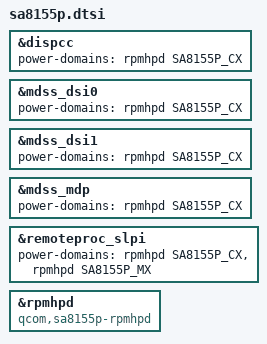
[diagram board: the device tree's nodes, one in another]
// SPDX-License-Identifier: BSD-3-Clause
/*
 * Copyright (c) 2023, Linaro Limited
 *
 * SA8155P is an automotive variant of SM8150, with some minor changes.
 * Most notably, the RPMhPD setup differs: MMCX and LCX/LMX rails are gone,
 * though the cmd-db doesn't reflect that and access attemps result in a bite.
 */

#include "sm8150.dtsi"

&dispcc {
	power-domains = <&rpmhpd SA8155P_CX>;
};

&mdss_dsi0 {
	power-domains = <&rpmhpd SA8155P_CX>;
};

&mdss_dsi1 {
	power-domains = <&rpmhpd SA8155P_CX>;
};

&mdss_mdp {
	power-domains = <&rpmhpd SA8155P_CX>;
};

&remoteproc_slpi {
	power-domains = <&rpmhpd SA8155P_CX>,
			<&rpmhpd SA8155P_MX>;
};

&rpmhpd {
	/*
	 * The bindings were crafted such that SA8155P PDs match their
	 * SM8150 counterparts to make it more maintainable and only
	 * necessitate adjusting entries that actually differ
	 */
	compatible = "qcom,sa8155p-rpmhpd";
};
